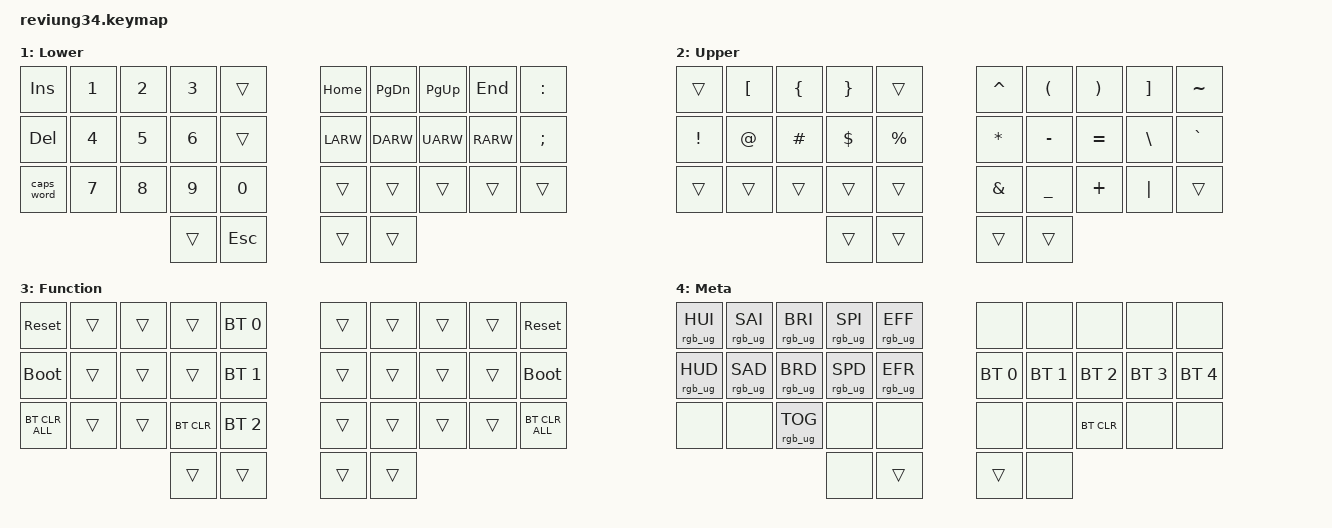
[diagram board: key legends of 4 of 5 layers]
/*
 * Copyright (c) 2023 The ZMK Contributors
 *
 * SPDX-License-Identifier: MIT
 */

#include <behaviors.dtsi>
#include <dt-bindings/zmk/bt.h>
#include <dt-bindings/zmk/keys.h>
#include <dt-bindings/zmk/rgb.h>

// Home row mods macro
//#define HRML(k1,k2,k3,k4) &ht LSHFT k1  &ht LALT k2  &ht LCTRL k3  &ht LGUI k4
//#define HRMR(k1,k2,k3,k4) &ht RGUI k1  &ht RCTRL k2  &ht RALT k3  &ht RSHFT k4
#define HRML(k1,k2,k3,k4) &ht LCTRL k1  &ht LALT k2  &ht LGUI k3  &ht LSHFT k4
#define HRMR(k1,k2,k3,k4) &ht RSHFT k1  &ht RGUI k2  &ht RALT k3  &ht RCTRL k4

/ {
    chosen {
        // 34 keys.
        zmk,matrix-transform = &dual_1u_transform;

        // 33 keys. Center two thumb keys replaced by a single 2u key. Remember to adjust your
        // keymap accordingly!
        // zmk,matrix-transform = &single_2u_transform;
    };

    behaviors {
        ht: hold_tap {
            label = "hold_tap";
            compatible = "zmk,behavior-hold-tap";
            #binding-cells = <2>;
            flavor = "tap-preferred";
            tapping-term-ms = <220>;
            quick-tap-ms = <150>;
            global-quick-tap;
            bindings = <&kp>, <&kp>;
        };
    };

    conditional_layers {
        compatible = "zmk,conditional-layers";
        tri_layer {
            if-layers = <1 2>;
            then-layer = <3>;
        };
    };

    keymap {
        compatible = "zmk,keymap";

        base {
            display-name = "Base";
            bindings = <
            &kp Q      &kp W      &kp F      &kp P      &kp G          &kp J      &kp L      &kp U      &kp Y      &kp BSPC
            HRML(A,        R,         S,         T)     &kp D          &kp H      HRMR(N,        E,         I,        O)
            &kp Z      &kp X      &kp C      &kp V      &kp B          &kp K      &kp M      &kp COMMA  &kp DOT    &kp FSLH
                                            &lt 2 TAB   &kp ENTER     &kp SPACE  &lt 1 BSPC
        //                                 ╰──────────┴──────────╯   ╰──────────┴──────────╯
            >;
        };

        lower {
            display-name = "Lower";
            bindings = <
        //╭──────────┬──────────┬──────────┬──────────┬──────────╮   ╭──────────┬──────────┬──────────┬──────────┬──────────╮
        //│ INSERT   │  1       │  2       │  3       │          │   │ HOME     │ PAGE DN  │ PAGE UP  │ END      │  :       │
            &kp INS    &kp N1     &kp N2     &kp N3     &trans         &kp HOME   &kp PG_DN  &kp PG_UP  &kp END    &kp COLON
        //├──────────┼──────────┼──────────┼──────────┼──────────┤   ├──────────┼──────────┼──────────┼──────────┼──────────┤
        //│ DELETE   │  4       │  5       │  6       │          │   │ LEFT     │ DOWN     │ UP       │ RIGHT    │  ;       │
            &kp DEL    &kp N4     &kp N5     &kp N6     &trans         &kp LARW   &kp DARW   &kp UARW   &kp RARW   &kp SEMI
        //├──────────┼──────────┼──────────┼──────────┼──────────┤   ├──────────┼──────────┼──────────┼──────────┼──────────┤
        //│ CAPS     │  7       │  8       │  9       │  0       │   │          │          │          │          │          │
           &caps_word  &kp N7     &kp N8     &kp N9     &kp N0         &trans     &trans     &trans     &trans     &trans
        //╰──────────┴──────────┴──────────┼──────────┼──────────┤   ├──────────┼──────────┼──────────┴──────────┴──────────╯
                                             &trans     &kp ESC        &trans     &trans
        //                                 ╰──────────┴──────────╯   ╰──────────┴──────────╯
            >;
        };

        upper {
            display-name = "Upper";
            bindings = <
        //╭──────────┬──────────┬──────────┬──────────┬──────────╮   ╭──────────┬──────────┬──────────┬──────────┬──────────╮
        //│          │  [       │  {       │  }       │          │   │  ^       │  (       │  )       │  ]       │  ~       │
            &trans     &kp LBKT   &kp LBRC   &kp RBRC   &trans         &kp CARET  &kp LPAR   &kp RPAR   &kp RBKT   &kp TILDE
        //├──────────┼──────────┼──────────┼──────────┼──────────┤   ├──────────┼──────────┼──────────┼──────────┼──────────┤
        //│  !       │  @       │  #       │  $       │  %       │   │  *       │  -       │  =       │  \       │  `       │
            &kp EXCL   &kp AT     &kp HASH   &kp DLLR   &kp PRCNT      &kp ASTRK  &kp MINUS  &kp EQUAL  &kp BSLH   &kp GRAVE
        //├──────────┼──────────┼──────────┼──────────┼──────────┤   ├──────────┼──────────┼──────────┼──────────┼──────────┤
        //│          │          │          │          │          │   │  &       │  _       │  +       │  │       │          │
            &trans     &trans     &trans     &trans     &trans         &kp AMPS   &kp UNDER  &kp PLUS   &kp PIPE   &trans
        //╰──────────┴──────────┴──────────┼──────────┼──────────┤   ├──────────┼──────────┼──────────┴──────────┴──────────╯
                                             &trans     &trans         &trans     &trans
        //                                 ╰──────────┴──────────╯   ╰──────────┴──────────╯
            >;
        };

        function {
            display-name = "Function";
            bindings = <
        //╭──────────┬──────────┬──────────┬──────────┬──────────╮   ╭──────────┬──────────┬──────────┬──────────┬──────────╮
        //│ RESET    │          │          │          │PROFILE 0 │   │          │          │          │          │  RESET   │
           &sys_reset  &trans     &trans     &trans    &bt BT_SEL 0    &trans     &trans     &trans     &trans    &sys_reset
        //├──────────┼──────────┼──────────┼──────────┼──────────┤   ├──────────┼──────────┼──────────┼──────────┼──────────┤
        //│BOOTLOADER│          │          │          │PROFILE 1 │   │          │          │          │          │BOOTLOADER│
          &bootloader  &trans     &trans     &trans    &bt BT_SEL 1    &trans     &trans     &trans     &trans    &bootloader
        //├──────────┼──────────┼──────────┼──────────┼──────────┤   ├──────────┼──────────┼──────────┼──────────┼──────────┤
        //│          │          │          │ CLEAR BT │PROFILE 2 │   │          │          │          │          │          │
        &bt BT_CLR_ALL     &trans     &trans    &bt BT_CLR &bt BT_SEL 2    &trans     &trans     &trans  &trans  &bt BT_CLR_ALL
        //╰──────────┴──────────┴──────────┼──────────┼──────────┤   ├──────────┼──────────┼──────────┴──────────┴──────────╯
                                             &trans     &trans         &trans     &trans
        //                                 ╰──────────┴──────────╯   ╰──────────┴──────────╯
            >;
        };

        meta {
            display-name = "Meta";
            bindings = <
            &rgb_ug RGB_HUI &rgb_ug RGB_SAI &rgb_ug RGB_BRI &rgb_ug RGB_SPI &rgb_ug RGB_EFF &none        &none        &none        &none        &none
            &rgb_ug RGB_HUD &rgb_ug RGB_SAD &rgb_ug RGB_BRD &rgb_ug RGB_SPD &rgb_ug RGB_EFR &bt BT_SEL 0 &bt BT_SEL 1 &bt BT_SEL 2 &bt BT_SEL 3 &bt BT_SEL 4
            &none           &none           &rgb_ug RGB_TOG &none           &none           &none        &none        &bt BT_CLR   &none        &none
                                            &none           &trans          &trans          &none
            >;
        };
    };
};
